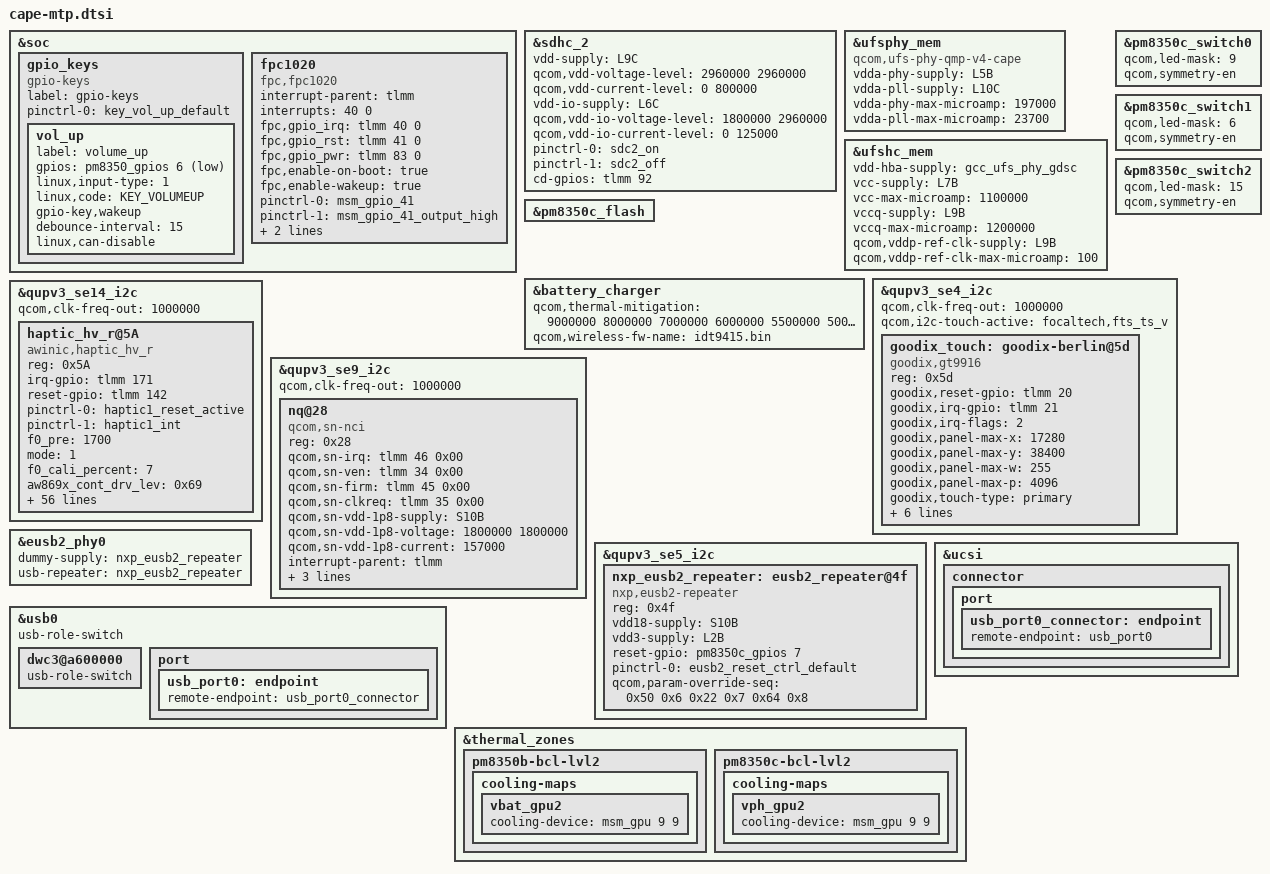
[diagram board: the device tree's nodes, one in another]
// SPDX-License-Identifier: BSD-3-Clause
/*
 * Copyright (c) 2022-2023, Qualcomm Innovation Center, Inc. All rights reserved.
 */

#include <dt-bindings/gpio/gpio.h>
#include <dt-bindings/input/input.h>
#include "cape-pmic-overlay.dtsi"
#include "waipio-thermal-overlay.dtsi"

&soc {
	gpio_keys {
		compatible = "gpio-keys";
		label = "gpio-keys";

		pinctrl-names = "default";
		pinctrl-0 = <&key_vol_up_default>;

		vol_up {
			label = "volume_up";
			gpios = <&pm8350_gpios 6 GPIO_ACTIVE_LOW>;
			linux,input-type = <1>;
			linux,code = <KEY_VOLUMEUP>;
			gpio-key,wakeup;
			debounce-interval = <15>;
			linux,can-disable;
		};
	};

	fpc1020 {
		compatible = "fpc,fpc1020";
		interrupt-parent = <&tlmm>;
		interrupts = <40 0>;
		fpc,gpio_irq = <&tlmm 40 0>;
		fpc,gpio_rst = <&tlmm 41 0>;
		fpc,gpio_pwr = <&tlmm 83 0>;
		fpc,enable-on-boot = "true";
		fpc,enable-wakeup = "true";
		pinctrl-names = "fpc1020_reset_reset", "fpc1020_reset_active",
				"fpc1020_irq_active", "fpc1020_irq_suspend";
		pinctrl-0 = <&msm_gpio_41>;
		pinctrl-1 = <&msm_gpio_41_output_high>;
		pinctrl-2 = <&msm_gpio_40>;
		pinctrl-3 = <&msm_gpio_40_suspend>;
		status = "ok";
	};
};

&sdhc_2 {
	status = "ok";
	vdd-supply = <&L9C>;
	qcom,vdd-voltage-level = <2960000 2960000>;
	qcom,vdd-current-level = <0 800000>;

	vdd-io-supply = <&L6C>;
	qcom,vdd-io-voltage-level = <1800000 2960000>;
	qcom,vdd-io-current-level = <0 125000>;

	pinctrl-names = "default", "sleep";
	pinctrl-0 = <&sdc2_on>;
	pinctrl-1 = <&sdc2_off>;

	cd-gpios = <&tlmm 92 GPIO_ACTIVE_HIGH>;
};

&ufsphy_mem {
	compatible = "qcom,ufs-phy-qmp-v4-cape";

	vdda-phy-supply = <&L5B>;
	vdda-pll-supply = <&L10C>;
	vdda-phy-max-microamp = <197000>;
	vdda-pll-max-microamp = <23700>;

	status = "ok";
};

&ufshc_mem {
	vdd-hba-supply = <&gcc_ufs_phy_gdsc>;

	vcc-supply = <&L7B>;
	vcc-max-microamp = <1100000>;

	vccq-supply = <&L9B>;
	vccq-max-microamp = <1200000>;

	qcom,vddp-ref-clk-supply = <&L9B>;
	qcom,vddp-ref-clk-max-microamp = <100>;

	status = "ok";
};

&pm8350c_switch0 {
	qcom,led-mask = <9>; /* Channels 1 & 4 */
	qcom,symmetry-en;
};

&pm8350c_switch1 {
	qcom,led-mask = <6>; /* Channels 2 & 3 */
	qcom,symmetry-en;
};

&pm8350c_switch2 {
	qcom,led-mask = <15>; /* All Channels */
	qcom,symmetry-en;
};

&pm8350c_flash {
	status = "ok";
};

&battery_charger {
	qcom,thermal-mitigation = <9000000 8000000 7000000 6000000 5500000 5000000 4000000 3000000 2500000 1500000 1000000 500000>;
	qcom,wireless-fw-name = "idt9415.bin";
};

&qupv3_se4_i2c {
	status = "ok";
	#address-cells = <1>;
	#size-cells = <0>;
	qcom,clk-freq-out = <1000000>;
	qcom,i2c-touch-active = "focaltech,fts_ts_v";

	goodix_touch: goodix-berlin@5d {
		compatible = "goodix,gt9916";
		reg = <0x5d>;
		goodix,reset-gpio = <&tlmm 20 0>;
		goodix,irq-gpio = <&tlmm 21 0x2800>;
		goodix,irq-flags = <2>;
		goodix,panel-max-x = <17280>;
		goodix,panel-max-y = <38400>;
		goodix,panel-max-w = <255>;
		goodix,panel-max-p = <4096>;
		goodix,touch-type = "primary";
		goodix,config-name = "goodix_cfg_group.bin";
		goodix,firmware-name = "goodix_firmware.bin";
		goodix,avdd-name = "avdd";
		goodix,iovdd-name = "iovdd";
		avdd-supply = <&L3C>;
		iovdd-supply = <&L8C>;
	};
};

&qupv3_se14_i2c {
	status = "ok";
	qcom,clk-freq-out = <1000000>;

	haptic_hv_r@5A {
		compatible = "awinic,haptic_hv_r";
		reg = <0x5A>;
		irq-gpio = <&tlmm 171 0>;
		reset-gpio = <&tlmm 142 0>;
		pinctrl-names = "pmx_haptic1_reset_active", "pmx_haptic1_int";
		pinctrl-0 = <&haptic1_reset_active>;
		pinctrl-1 = <&haptic1_int>;
		f0_pre = <1700>;
		mode = /bits/ 8 <1>;
		f0_cali_percent = /bits/ 8 <7>;

		/*******************************aw869x*******************************/
		aw869x_cont_drv_lev = /bits/ 8 <0x69>;
		aw869x_cont_drv_lvl_ov = /bits/ 8 <0x7D>;
		aw869x_cont_td = <0x009A>;
		aw869x_cont_zc_thr = <0x0FF1>;
		aw869x_cont_num_brk = /bits/ 8 <3>;
		aw869x_f0_coeff = <0x0104>;
		aw869x_duration_time = /bits/ 8 <0x14 0x1E 0x3C>;
		aw869x_f0_trace_parameter = /bits/ 8 <0x05 0x03 0x02 0x0F>;
		aw869x_bemf_config = /bits/ 8 <0x10 0x08 0x03 0xF8>;
		aw869x_tset = /bits/ 8 <0x12>;
		aw869x_r_spare = /bits/ 8 <0x68>;
		aw869x_sw_brake = /bits/ 8 <0x2C>;
		aw869x_max_bst_vol = /bits/ 8 <0x1F>;
		aw869x_bstdbg = /bits/ 8 <0x30 0xEB 0xD4 0x00 0x00 0x00>;

		/******************************aw869xx*******************************/
		aw869xx_brk_bst_md = /bits/ 8 <0x00>;
		aw869xx_cont_drv1_lvl = /bits/ 8 <0x7F>;
		aw869xx_cont_drv1_time = /bits/ 8 <0x04>;
		aw869xx_cont_drv2_lvl = /bits/ 8 <0x36>;
		aw869xx_cont_drv2_time = /bits/ 8 <0x14>;
		aw869xx_cont_drv_width = /bits/ 8 <0x6A>;
		aw869xx_cont_brk_time = /bits/ 8 <0x00>;
		aw869xx_cont_tset = /bits/ 8 <0x06>;
		aw869xx_cont_bemf_set = /bits/ 8 <0x02>;
		aw869xx_cont_wait_num = /bits/ 8 <0x06>;
		aw869xx_cont_bst_brk_gain = /bits/ 8 <0x05>;
		aw869xx_cont_brk_gain = /bits/ 8 <0x08>;
		aw869xx_cont_track_margin = /bits/ 8 <0x12>;
		aw869xx_d2s_gain = /bits/ 8 <0x04>;
		aw869xx_bstcfg = /bits/ 8 <0x20 0x24 0x96 0x40 0x11>;
		aw869xx_bst_vol_default = /bits/ 8 <0x16>;
		aw869xx_bst_vol_ram = /bits/ 8 <0x24>;
		aw869xx_bst_vol_rtp = /bits/ 8 <0x15>;
		aw869xx_max_bst_vol = /bits/ 8 <0x3F>;
		aw869xx_prctmode = /bits/ 8 <0x2D 0x3E 0x3F>;
		aw869xx_sine_array = <0x05B2FFEF>;
		aw869xx_trig_config = <0x00000105 0x01050000 0x01000001 0x00020000 0x01000001 0x00020000>;

		/******************************aw8692x*******************************/
		aw8692x_brk_bst_md = /bits/ 8 <0x00>;
		aw8692x_cont_drv1_lvl = /bits/ 8 <0x7F>;
		aw8692x_cont_drv1_time = /bits/ 8 <0x04>;
		aw8692x_cont_drv2_lvl = /bits/ 8 <0x50>;
		aw8692x_cont_drv2_time = /bits/ 8 <0x06>;
		aw8692x_cont_drv_width = /bits/ 8 <0x6A>;
		aw8692x_cont_tset = /bits/ 8 <0x06>;
		aw8692x_cont_bemf_set = /bits/ 8 <0x02>;
		aw8692x_cont_wait_num = /bits/ 8 <0x06>;
		aw8692x_cont_brk_time = /bits/ 8 <0x08>;
		aw8692x_cont_bst_brk_gain = /bits/ 8 <0x05>;
		aw8692x_cont_brk_gain = /bits/ 8 <0x08>;
		aw8692x_cont_track_margin = /bits/ 8 <0x0C>;
		aw8692x_d2s_gain = /bits/ 8 <0x04>;
		aw8692x_bst_vol_default = /bits/ 8 <0x58>;
		aw8692x_bst_vol_ram = /bits/ 8 <0x58>;
		aw8692x_bst_vol_rtp = /bits/ 8 <0x58>;
		aw8692x_max_bst_vol = /bits/ 8 <0x7F>;
		aw8692x_trig_config = <0x00000105 0x01050000 0x01000001 0x00020000 0x01000001 0x00020000>;
	};
};

&qupv3_se9_i2c {
	status = "ok";
	qcom,clk-freq-out = <1000000>;
	#address-cells = <1>;
	#size-cells = <0>;

	nq@28 {
		compatible = "qcom,sn-nci";
		reg = <0x28>;
		qcom,sn-irq = <&tlmm 46 0x00>;
		qcom,sn-ven = <&tlmm 34 0x00>;
		qcom,sn-firm = <&tlmm 45 0x00>;
		qcom,sn-clkreq = <&tlmm 35 0x00>;
		qcom,sn-vdd-1p8-supply = <&S10B>;
		qcom,sn-vdd-1p8-voltage = <1800000 1800000>;
		qcom,sn-vdd-1p8-current = <157000>;
		interrupt-parent = <&tlmm>;
		interrupts = <46 0>;
		interrupt-names = "nfc_irq";
		pinctrl-names = "nfc_active", "nfc_suspend";
		pinctrl-0 = <&nfc_int_active &nfc_enable_active>;
		pinctrl-1 = <&nfc_int_suspend &nfc_enable_suspend>;
	};
};

&qupv3_se5_i2c {
	status = "ok";
	#address-cells = <1>;
	#size-cells = <0>;

	nxp_eusb2_repeater: eusb2_repeater@4f {
		compatible = "nxp,eusb2-repeater";
		reg = <0x4f>;
		vdd18-supply = <&S10B>;
		vdd3-supply = <&L2B>;
		reset-gpio = <&pm8350c_gpios 7 GPIO_ACTIVE_HIGH>;
		pinctrl-names = "default";
		pinctrl-0 = <&eusb2_reset_ctrl_default>;
		qcom,param-override-seq = <0x50 0x6 0x22 0x7 0x64 0x8>;
	};
};

&eusb2_phy0 {
	dummy-supply = <&nxp_eusb2_repeater>;
	usb-repeater = <&nxp_eusb2_repeater>;
};

&usb0 {
	usb-role-switch;

	dwc3@a600000 {
		usb-role-switch;
	};

	port {
		usb_port0: endpoint {
			remote-endpoint = <&usb_port0_connector>;
		};
	};
};

&ucsi {
	connector {
		port {
			usb_port0_connector: endpoint {
				remote-endpoint = <&usb_port0>;
			};
		};
	};
};

&thermal_zones {
	pm8350b-bcl-lvl2 {
		cooling-maps {
			vbat_gpu2 {
				cooling-device = <&msm_gpu 9 9>;
			};
		};
	};

	pm8350c-bcl-lvl2 {
		cooling-maps {
			vph_gpu2 {
				cooling-device = <&msm_gpu 9 9>;
			};
		};
	};
};
